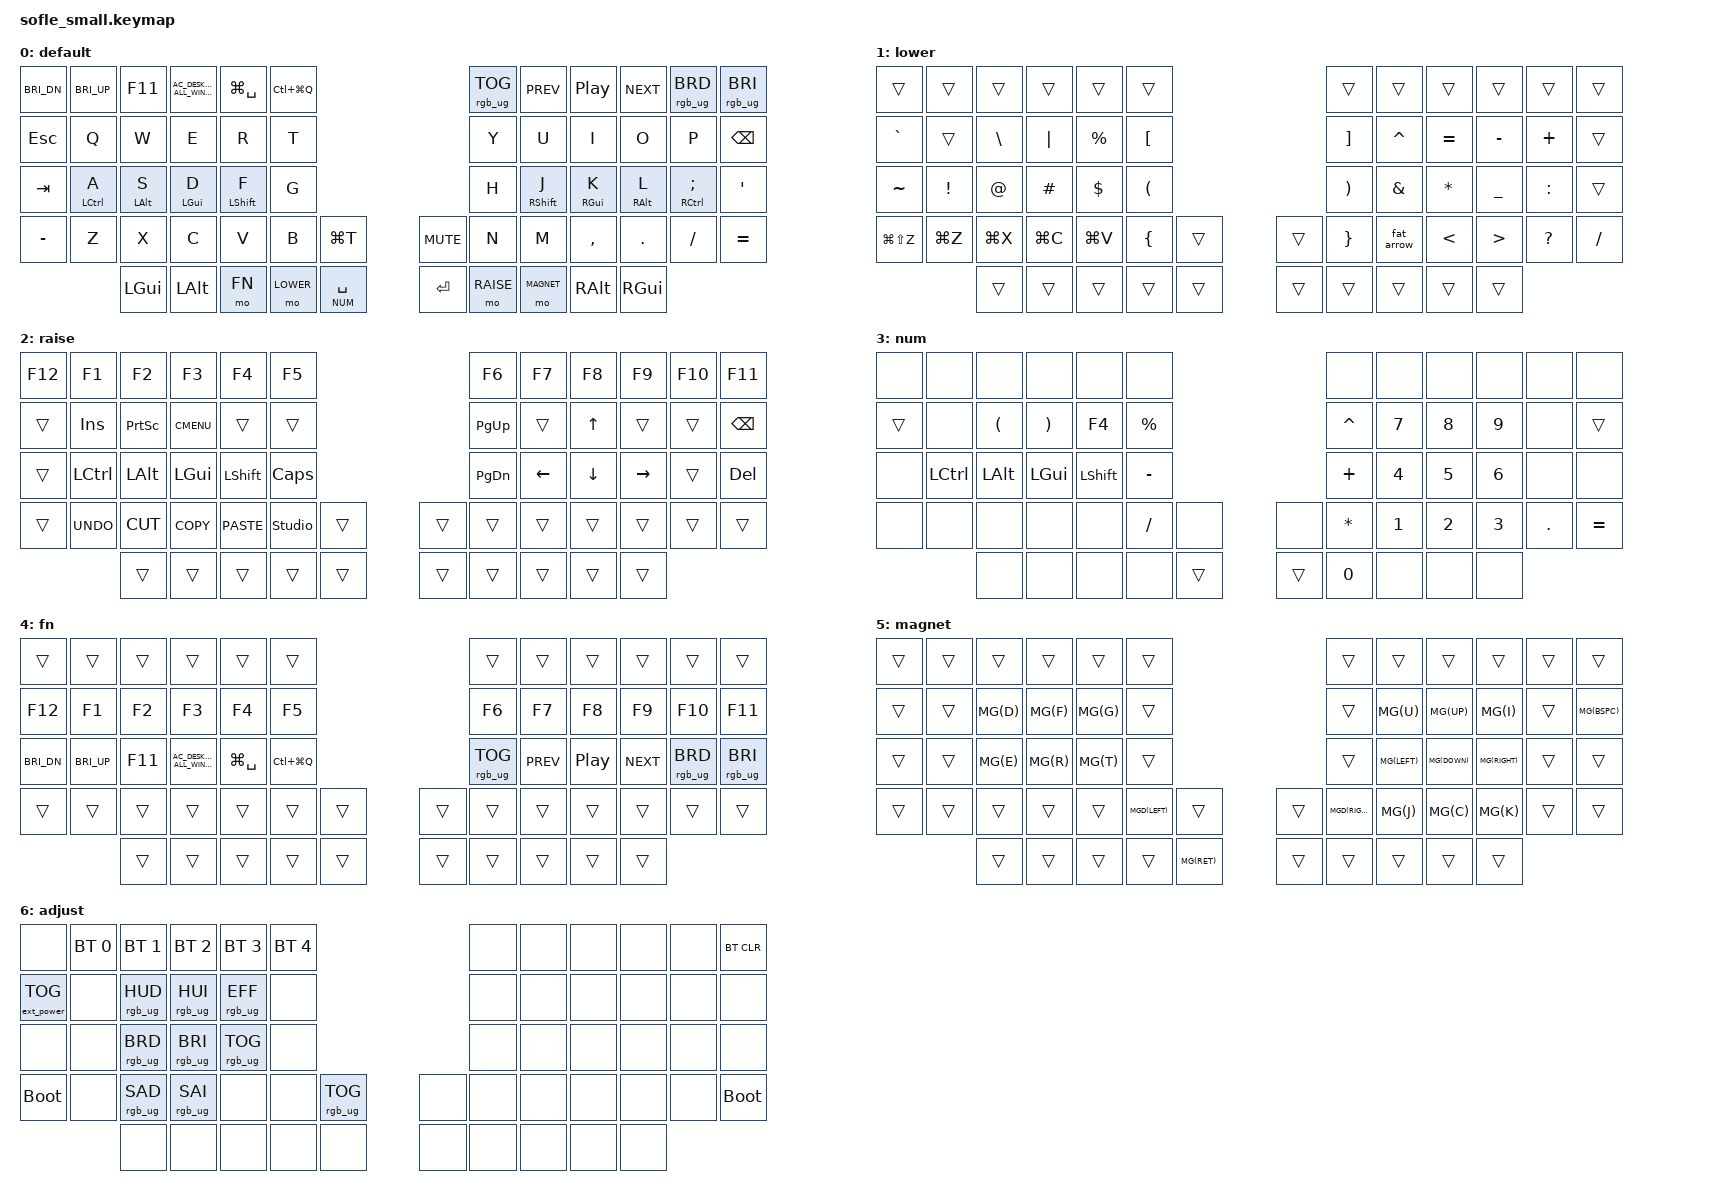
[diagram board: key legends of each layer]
/*
* Copyright (c) 2020 The ZMK Contributors
*
* SPDX-License-Identifier: MIT
*/

#include <behaviors.dtsi>
#include <dt-bindings/zmk/keys.h>
#include <dt-bindings/zmk/bt.h>
#include <dt-bindings/zmk/rgb.h>
#include <dt-bindings/zmk/ext_power.h>

#define BASE 0
#define LOWER 1
#define RAISE 2
#define NUM 3
#define FN 4
#define MAGNET 5
#define ADJUST 6

// Magnet (macOS window manager) shortcuts are all Ctrl+Option+<key>
#define MG(k) &kp LC(LA(k))
#define MGD(k) &kp LC(LA(LG(k)))

/ {

  behaviors {
    // Home row mods: tap = letter, hold = modifier. Positional: the hold only triggers when the next key
    // is on the opposite hand (or a thumb key), so same-hand rolls still type letters.
    // Key positions: 5 rows, rows 0-2 are 12 keys, row 3 is 14 (incl. 2 encoder keys), row 4 is 10.
    hml: homerow_mod_left {
      compatible = "zmk,behavior-hold-tap";
      #binding-cells = <2>;
      flavor = "balanced";
      tapping-term-ms = <280>;
      quick-tap-ms = <175>;
      require-prior-idle-ms = <150>;
      hold-trigger-on-release;
      hold-trigger-key-positions = <6 7 8 9 10 11 18 19 20 21 22 23 30 31 32 33 34 35 44 45 46 47 48 49 50 51 52 53 54 55 56 57 58 59>;
      bindings = <&kp>, <&kp>;
    };

    hmr: homerow_mod_right {
      compatible = "zmk,behavior-hold-tap";
      #binding-cells = <2>;
      flavor = "balanced";
      tapping-term-ms = <280>;
      quick-tap-ms = <175>;
      require-prior-idle-ms = <150>;
      hold-trigger-on-release;
      hold-trigger-key-positions = <0 1 2 3 4 5 12 13 14 15 16 17 24 25 26 27 28 29 36 37 38 39 40 41 50 51 52 53 54 55 56 57 58 59>;
      bindings = <&kp>, <&kp>;
    };

    // Encoder behavior: clockwise = brighter, counter-clockwise = dimmer
    // (this board's encoders report reversed, same as the volume bindings use VOL_DN first)
    rgb_enc: rgb_encoder {
      compatible = "zmk,behavior-sensor-rotate";
      #sensor-binding-cells = <0>;
      bindings = <&rgb_ug RGB_BRD>, <&rgb_ug RGB_BRI>;
    };
  };

  macros {
    // => (arrow function), for the LOWER layer
    ZMK_MACRO(fat_arrow, bindings = <&kp EQUAL &kp GT>;)
  };

  conditional_layers {
    compatible = "zmk,conditional-layers";
    // Activate ADJUST layer by pressing raise and lower
    adjust_layer {
      if-layers = <LOWER RAISE>;
      then-layer = <ADJUST>;
    };
  };

  keymap {
    compatible = "zmk,keymap";

    default_layer {
      display-name = "default";
      // Thumbs: hold LOWER = symbols, hold RAISE = navigation, LOWER + RAISE = adjust, hold FN = function keys,
      // hold MAGNET (right thumb, where CTRL was) = Magnet window shortcuts
      // SPACE is a layer-tap: tap = Space, hold = NUM layer
      // Top row = the FN layer's home row (same as the full layout): DESK = Show Desktop (F11), MISSN = Mission Control,
      // SPOT = Spotlight (Cmd+Space), LOCK = Ctrl+Cmd+Q, LED = RGB underglow. Numbers are on NUM, ` and \ on LOWER
      // ------------------------------------------------------------------------------------------------------------
      // |  BRI- |BRI+ |DESK |MISSN | SPOT | LOCK |                   |  LED | PREV  | PLAY  | NEXT |  LED- |  LED+ |
      // |  ESC  |  Q  |  W  |  E   |  R   |  T   |                   |  Y   |  U    |  I    |  O   |   P   | BKSPC |
      // |  TAB  |A/CTL|S/OPT|D/CMD |F/SHFT|  G   |                   |  H   |J/SHFT | K/CMD |L/OPT | ;/CTL |   '   |
      // |   -   |  Z  |  X  |  C   |  V   |  B   | NEWTAB |  | MUTE  |  N   |  M    |  ,    |  .   |   /   |   =   |
      //               | GUI | ALT  |  FN  | LOWER|  SPACE |  | ENTER | RAISE|MAGNET | ALT   | GUI  |
      bindings = <
        &kp C_BRI_DN &kp C_BRI_UP &kp F11 &kp C_AC_DESKTOP_SHOW_ALL_WINDOWS &kp LG(SPACE) &kp LC(LG(Q))           &rgb_ug RGB_TOG &kp C_PREV &kp C_PP &kp C_NEXT &rgb_ug RGB_BRD &rgb_ug RGB_BRI
        &kp ESC   &kp Q  &kp W    &kp E    &kp R     &kp T                            &kp Y  &kp U     &kp I     &kp O    &kp P    &kp BSPC
        &kp TAB   &hml LCTRL A &hml LALT S &hml LGUI D &hml LSHFT F &kp G            &kp H  &hmr RSHFT J &hmr RGUI K &hmr RALT L &hmr RCTRL SEMI &kp SQT
        &kp MINUS &kp Z  &kp X    &kp C    &kp V     &kp B   &kp LG(T) &kp C_MUTE    &kp N  &kp M     &kp COMMA &kp DOT  &kp FSLH &kp EQUAL
        &kp LGUI &kp LALT  &mo FN    &mo LOWER  &lt NUM SPACE  &kp RET  &mo RAISE  &mo MAGNET &kp RALT  &kp RGUI
      >;

      // Left encoder: previous / next tab (Cmd+Shift+[ / ]), click = new tab (Cmd+T). Right encoder: volume, click = mute
      sensor-bindings = <&inc_dec_kp LG(LS(LBKT)) LG(LS(RBKT)) &inc_dec_kp C_VOL_DN C_VOL_UP>;
    };

    lower_layer {
      display-name = "lower";
      // Symbols (merged with the old CODE layer). Brackets pair up across the two index-finger columns:
      // [ ] on T Y, ( ) on G H, { } on B N. Home row = the shifted numbers in number-row order, around the ( )
      // Middle fingers get the most used: | on E, = on I. The rest sit as close to their QWERTY keys as possible:
      // ` ~ top left, % ^ next to [ ] (5 6 sit above T Y), - + top right with _ below -, : ? < > on their own keys (; / , .),
      // / next to ? (its QWERTY key partner), => (macro) on M next to < >. ESC position = `, BKSPC passes through
      // UNDO/CUT/COPY/PASTE/REDO = Cmd+Z/X/C/V and Cmd+Shift+Z, one-handed with the left-thumb LOWER key
      // ------------------------------------------------------------------------------------------------------------
      // |       |     |     |      |      |      |                   |      |       |       |      |       |       |
      // |   `   |     |  \  |  |   |  %   |  [   |                   |  ]   |  ^    |  =    |  -   |   +   | BKSPC |
      // |   ~   |  !  |  @  |  #   |  $   |  (   |                   |  )   |  &    |  *    |  _   |   :   |       |
      // | REDO  |UNDO | CUT | COPY |PASTE |  {   |        |  |       |  }   |  =>   |  <    |  >   |   ?   |   /   |
      //               |     |      |      |      |        |  |       |      |       |       |      |
      bindings = <
        &trans        &trans    &trans    &trans    &trans    &trans                        &trans    &trans   &trans    &trans    &trans    &trans
        &kp GRAVE     &trans    &kp BSLH  &kp PIPE  &kp PRCNT &kp LBKT                      &kp RBKT  &kp CARET &kp EQUAL &kp MINUS &kp PLUS &trans
        &kp TILDE     &kp EXCL  &kp AT    &kp HASH  &kp DLLR  &kp LPAR                      &kp RPAR  &kp AMPS &kp ASTRK &kp UNDER &kp COLON &trans
        &kp LG(LS(Z)) &kp LG(Z) &kp LG(X) &kp LG(C) &kp LG(V) &kp LBRC  &trans    &trans    &kp RBRC  &fat_arrow &kp LT  &kp GT    &kp QMARK &kp FSLH
        &trans        &trans    &trans    &trans    &trans    &trans    &trans    &trans    &trans    &trans
      >;

      sensor-bindings = <&inc_dec_kp C_VOL_DN C_VOL_UP &inc_dec_kp C_PREV C_NEXT>;
    };

    raise_layer {
      display-name = "raise";
      // Navigation. Left home row = plain modifiers in home row mod order, to combine with the arrows
      // ------------------------------------------------------------------------------------------------------------
      // |  F12  |  F1  |  F2  |  F3   |  F4   |  F5  |                |  F6  |  F7  |  F8   |  F9  |  F10  |  F11  |
      // |       | INS  | PSCR | GUI   |       |      |                | PGUP |      |   ^   |      |       | BKSPC |
      // |       | CTRL | OPT  |  CMD  | SHIFT | CAPS |                | PGDN |   <- |   v   |  ->  |       |  DEL  |
      // |       | UNDO | CUT  | COPY  | PASTE | UNLK |      |  |      |      |      |       |      |       |       |
      //                |      |       |       |      |      |  |      |      |      |       |      |
      bindings = <
        &kp F12    &kp F1       &kp F2       &kp F3       &kp F4       &kp F5                        &kp F6    &kp F7    &kp F8   &kp F9    &kp F10 &kp F11
        &trans     &kp INS      &kp PSCRN    &kp K_CMENU  &trans       &trans                        &kp PG_UP &trans    &kp UP   &trans    &trans  &kp BSPC
        &trans     &kp LCTRL    &kp LALT     &kp LGUI     &kp LSHFT    &kp CLCK                      &kp PG_DN &kp LEFT  &kp DOWN &kp RIGHT &trans  &kp DEL
        &trans     &kp K_UNDO   &kp K_CUT    &kp K_COPY   &kp K_PASTE  &studio_unlock        &trans  &trans  &trans    &trans    &trans   &trans    &trans  &trans
        &trans       &trans       &trans       &trans        &trans  &trans  &trans    &trans    &trans   &trans
      >;

      sensor-bindings = <&inc_dec_kp C_VOL_DN C_VOL_UP &inc_dec_kp C_PREV C_NEXT>;
    };

    num_layer {
      display-name = "num";
      // Hold SPACE. Numpad on the right hand with the math operators around it, = where it is on the default layer
      // Left hand: parentheses and F4 (toggles Excel's $ reference lock)
      // Left home row = plain modifiers in home row mod order (no tap-hold). Cmd+number = hold D + the number
      // 0 is on the right thumb key next to ENTER (below 1)
      // Blank keys do nothing (&none). ESC, BKSPC, SPACE and ENTER pass through to the default layer
      // ------------------------------------------------------------------------------------------------------------
      // |       |     |     |      |      |      |                   |      |       |       |      |       |       |
      // |  ESC  |     |  (  |  )   |  F4  |  %   |                   |  ^   |  7    |  8    |  9   |       | BKSPC |
      // |       |CTRL | OPT | CMD  |SHIFT |  -   |                   |  +   |  4    |  5    |  6   |       |       |
      // |       |     |     |      |      |  /   |        |  |       |  *   |  1    |  2    |  3   |   .   |   =   |
      //               |     |      |      |      |  SPACE |  | ENTER |  0   |       |       |      |
      bindings = <
        &none     &none     &none     &none     &none     &none                         &none     &none    &none     &none     &none     &none
        &trans    &none     &kp LPAR  &kp RPAR  &kp F4    &kp PRCNT                     &kp CARET &kp N7   &kp N8    &kp N9    &none     &trans
        &none     &kp LCTRL &kp LALT  &kp LGUI  &kp LSHFT &kp MINUS                     &kp PLUS  &kp N4   &kp N5    &kp N6    &none     &none
        &none     &none     &none     &none     &none     &kp FSLH  &none     &none     &kp ASTRK &kp N1   &kp N2    &kp N3    &kp DOT   &kp EQUAL
        &none     &none     &none     &none     &trans    &trans    &kp N0    &none     &none     &none
      >;
    };

    fn_layer {
      display-name = "fn";
      // Hold FN (left thumb, where CTRL was). F1-F10 sit on the letters below 1-0, F11 on BKSPC, F12 on ESC
      // Home row (from the full layout): DESK = Show Desktop (F11), MISSN = Mission Control, SPOT = Spotlight (Cmd+Space),
      // LOCK = Ctrl+Cmd+Q, LED = RGB underglow on/off, LED-/LED+ = underglow brightness
      // ------------------------------------------------------------------------------------------------------------
      // |       |      |      |       |       |      |                |      |      |       |      |       |       |
      // |  F12  |  F1  |  F2  |  F3   |  F4   |  F5  |                |  F6  |  F7  |  F8   |  F9  |  F10  |  F11  |
      // |  BRI- | BRI+ | DESK | MISSN | SPOT  | LOCK |                |  LED | PREV | PLAY  | NEXT |  LED- |  LED+ |
      // |       |      |      |       |       |      |      |  |      |      |      |       |      |       |       |
      //                |      |       |       |      |      |  |      |      |      |       |      |
      bindings = <
        &trans       &trans       &trans  &trans                            &trans        &trans                  &trans          &trans     &trans   &trans     &trans          &trans
        &kp F12      &kp F1       &kp F2  &kp F3                            &kp F4        &kp F5                  &kp F6          &kp F7     &kp F8   &kp F9     &kp F10         &kp F11
        &kp C_BRI_DN &kp C_BRI_UP &kp F11 &kp C_AC_DESKTOP_SHOW_ALL_WINDOWS &kp LG(SPACE) &kp LC(LG(Q))           &rgb_ug RGB_TOG &kp C_PREV &kp C_PP &kp C_NEXT &rgb_ug RGB_BRD &rgb_ug RGB_BRI
        &trans       &trans       &trans  &trans                            &trans        &trans  &trans  &trans  &trans          &trans     &trans   &trans     &trans          &trans
        &trans       &trans       &trans  &trans                            &trans        &trans                  &trans          &trans     &trans   &trans
      >;
    };

    magnet_layer {
      display-name = "magnet";
      // Hold the right-thumb MAGNET key, then press one key below (Ctrl+Opt+key is sent). Letters match Magnet's own.
      // Halves use the same keys as the arrows on the RAISE layer (I = up, J/K/L = left/down/right)
      // MAX is on the SPACE key (the right thumb is holding MAGNET), CENTER on the , key between BL and BR
      // -----------------------------------------------------------------------------------------------------------------
      // |       |       |       |       |       |       |               |       |       |       |       |       |       |
      // |       |       |  L1/3 |  C1/3 |  R1/3 |       |               |       |   TL  |  TOP  |   TR  |       | RSTOR |
      // |       |       |  L2/3 |  C2/3 |  R2/3 |       |               |       |  LEFT | BOTTOM| RIGHT |       |       |
      // |       |       |       |       |       | PREVD |       |       | NEXTD |   BL  | CENTER|   BR  |       |       |
      //         |       |       |       |       |  MAX  |               |       |       |       |       |       |
      bindings = <
        &trans &trans &trans &trans &trans &trans                    &trans     &trans   &trans   &trans    &trans &trans
        &trans &trans MG(D)  MG(F)  MG(G)  &trans                    &trans     MG(U)    MG(UP)   MG(I)     &trans MG(BSPC)
        &trans &trans MG(E)  MG(R)  MG(T)  &trans                    &trans     MG(LEFT) MG(DOWN) MG(RIGHT) &trans &trans
        &trans &trans &trans &trans &trans MGD(LEFT)  &trans &trans  MGD(RIGHT) MG(J)    MG(C)    MG(K)     &trans &trans
               &trans &trans &trans &trans  MG(RET)                  &trans     &trans   &trans   &trans    &trans
      >;

      // Both encoders: previous / next tab (Cmd+Shift+[ / ]: Chrome, Terminal, iTerm2, VS Code editors)
      // (this board's encoders report reversed: the first binding fires when twisting left)
      sensor-bindings = <&inc_dec_kp LG(LS(LBKT)) LG(LS(RBKT)) &inc_dec_kp LG(LS(LBKT)) LG(LS(RBKT))>;
    };

    adjust_layer {
      display-name = "adjust";
      // BOOT = &bootloader: resets the half whose key you press into UF2 mode (no pin needed)
      // -----------------------------------------------------------------------------------------------------------------
      // |       |  BT1  |  BT2  |  BT3  |  BT4  |  BT5  |               |       |       |       |       |       | BTCLR |
      // | EXTPWR|       |RGB_HUD|RGB_HUI|RGB_EFF|       |               |       |       |       |       |       |       |
      // |       |       |RGB_BRD|RGB_BRI|RGB_TOG|       |               |       |       |       |       |       |       |
      // |  BOOT |       |RGB_SAD|RGB_SAI|       |       |RGB_TOG|       |       |       |       |       |       |  BOOT |
      //         |       |       |       |       |       |               |       |       |       |       |       |
      bindings = <
        &none             &bt BT_SEL 0    &bt BT_SEL 1    &bt BT_SEL 2    &bt BT_SEL 3    &bt BT_SEL 4                            &none &none &none &none &none &bt BT_CLR
        &ext_power EP_TOG &none           &rgb_ug RGB_HUD &rgb_ug RGB_HUI &rgb_ug RGB_EFF &none                                   &none &none &none &none &none &none
        &none             &none           &rgb_ug RGB_BRD &rgb_ug RGB_BRI &rgb_ug RGB_TOG &none                                   &none &none &none &none &none &none
        &bootloader       &none           &rgb_ug RGB_SAD &rgb_ug RGB_SAI &none           &none            &rgb_ug RGB_TOG &none  &none &none &none &none &none &bootloader
        &none           &none           &none           &none            &none           &none  &none &none &none &none
      >;

      // Left encoder: RGB brightness (click toggles RGB, see RGB_TOG above); right encoder unchanged
      sensor-bindings = <&rgb_enc &inc_dec_kp C_PREV C_NEXT>;
    };
  };
};
